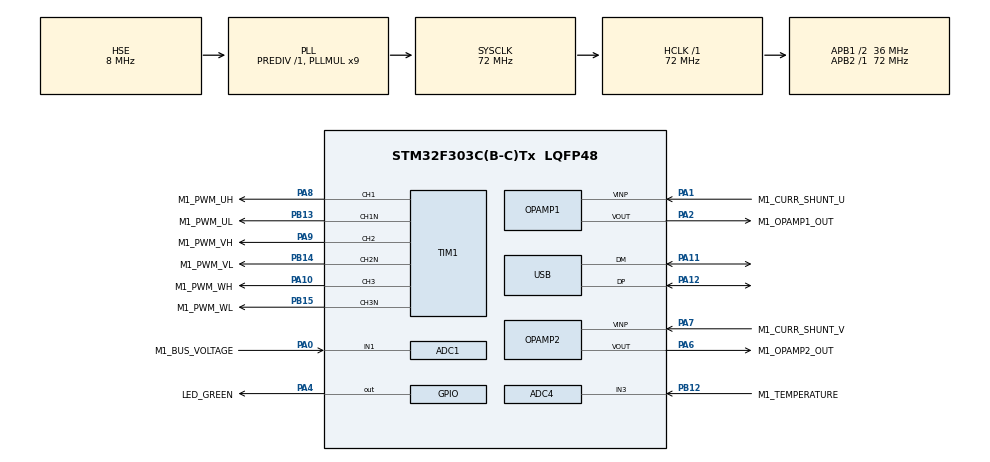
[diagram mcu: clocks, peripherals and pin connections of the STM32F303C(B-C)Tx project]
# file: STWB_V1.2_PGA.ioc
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ADC1.Channel-1\#ChannelRegularConversion=ADC_CHANNEL_1
ADC1.ClockPrescaler=ADC_CLOCK_SYNC_PCLK_DIV4
ADC1.ContinuousConvMode=DISABLE
ADC1.DMAContinuousRequests=DISABLE
ADC1.DataAlign=ADC_DATAALIGN_LEFT
ADC1.DiscontinuousConvMode=DISABLE
ADC1.EOCSelection=ADC_EOC_SINGLE_CONV
ADC1.EnableAnalogWatchDog1=false
ADC1.EnableAnalogWatchDog2=false
ADC1.EnableAnalogWatchDog3=false
ADC1.EnableInjectedConversion=ENABLE
ADC1.EnableRegularConversion=ENABLE
ADC1.ExternalTrigConv=ADC_SOFTWARE_START
ADC1.ExternalTrigConvEdge=ADC_EXTERNALTRIGCONVEDGE_NONE
ADC1.ExternalTrigInjecConv=ADC_EXTERNALTRIGINJECCONV_T1_TRGO
ADC1.ExternalTrigInjecConvEdge=ADC_EXTERNALTRIGINJECCONV_EDGE_RISING
ADC1.InjNumberOfConversion=1
ADC1.InjectedChannel-1\#ChannelInjectedConversion=ADC_CHANNEL_3
ADC1.InjectedConvMode=None
ADC1.InjectedOffset-1\#ChannelInjectedConversion=0
ADC1.InjectedOffsetNumber-1\#ChannelInjectedConversion=ADC_OFFSET_NONE
ADC1.InjectedRank-1\#ChannelInjectedConversion=1
ADC1.InjectedSamplingTime-1\#ChannelInjectedConversion=ADC_SAMPLETIME_7CYCLES_5
ADC1.LowPowerAutoWait=DISABLE
ADC1.NbrOfConversion=1
ADC1.NbrOfConversionFlag=1
ADC1.Offset-1\#ChannelRegularConversion=0
ADC1.OffsetNumber-1\#ChannelRegularConversion=ADC_OFFSET_NONE
ADC1.Overrun=ADC_OVR_DATA_PRESERVED
ADC1.QueueInjectedContext=ENABLE
ADC1.Rank-1\#ChannelRegularConversion=1
ADC1.Resolution=ADC_RESOLUTION_12B
ADC1.SamplingTime-1\#ChannelRegularConversion=ADC_SAMPLETIME_61CYCLES_5
ADC1.ScanConvMode=ADC_SCAN_DISABLE
ADC1.master=1
ADC2.ClockPrescaler=ADC_CLOCK_SYNC_PCLK_DIV4
ADC2.ContinuousConvMode=DISABLE
ADC2.DMAContinuousRequests=DISABLE
ADC2.DataAlign=ADC_DATAALIGN_LEFT
ADC2.DiscontinuousConvMode=DISABLE
ADC2.EOCSelection=ADC_EOC_SINGLE_CONV
ADC2.EnableAnalogWatchDog1=false
ADC2.EnableAnalogWatchDog2=false
ADC2.EnableAnalogWatchDog3=false
ADC2.EnableInjectedConversion=ENABLE
ADC2.EnableRegularConversion=DISABLE
ADC2.ExternalTrigInjecConv=ADC_EXTERNALTRIGINJECCONV_T1_TRGO
ADC2.ExternalTrigInjecConvEdge=ADC_EXTERNALTRIGINJECCONV_EDGE_RISING
ADC2.InjNumberOfConversion=1
ADC2.InjectedChannel-1\#ChannelInjectedConversion=ADC_CHANNEL_3
ADC2.InjectedConvMode=None
ADC2.InjectedOffset-1\#ChannelInjectedConversion=0
ADC2.InjectedOffsetNumber-1\#ChannelInjectedConversion=ADC_OFFSET_NONE
ADC2.InjectedRank-1\#ChannelInjectedConversion=1
ADC2.InjectedSamplingTime-1\#ChannelInjectedConversion=ADC_SAMPLETIME_7CYCLES_5
ADC2.LowPowerAutoWait=DISABLE
ADC2.Overrun=ADC_OVR_DATA_PRESERVED
ADC2.QueueInjectedContext=ENABLE
ADC2.Resolution=ADC_RESOLUTION_12B
ADC2.ScanConvMode=ADC_SCAN_DISABLE
ADC2.master=1
ADC4.Channel-1\#ChannelRegularConversion=ADC_CHANNEL_3
ADC4.ClockPrescaler=ADC_CLOCK_SYNC_PCLK_DIV4
ADC4.ContinuousConvMode=DISABLE
ADC4.DMAContinuousRequests=DISABLE
ADC4.DataAlign=ADC_DATAALIGN_LEFT
ADC4.DiscontinuousConvMode=DISABLE
ADC4.EOCSelection=ADC_EOC_SINGLE_CONV
ADC4.EnableAnalogWatchDog1=false
ADC4.EnableAnalogWatchDog2=false
ADC4.EnableAnalogWatchDog3=false
ADC4.EnableRegularConversion=ENABLE
ADC4.ExternalTrigConv=ADC_SOFTWARE_START
ADC4.ExternalTrigConvEdge=ADC_EXTERNALTRIGCONVEDGE_NONE
ADC4.LowPowerAutoWait=DISABLE
ADC4.NbrOfConversion=1
ADC4.NbrOfConversionFlag=1
ADC4.Offset-1\#ChannelRegularConversion=0
ADC4.OffsetNumber-1\#ChannelRegularConversion=ADC_OFFSET_NONE
ADC4.Overrun=ADC_OVR_DATA_PRESERVED
ADC4.Rank-1\#ChannelRegularConversion=1
ADC4.Resolution=ADC_RESOLUTION_12B
ADC4.SamplingTime-1\#ChannelRegularConversion=ADC_SAMPLETIME_61CYCLES_5
ADC4.ScanConvMode=ADC_SCAN_DISABLE
ADC4.master=1
ExtraMW=MotorControl
ExtraMW.MotorControl.Config=MotorControl
ExtraMW.MotorControl.Mode=MotorControl
ExtraMW.MotorControl.Root=MCSDK_v5.4.4-Full/MotorControl
ExtraMW.MotorControl.Template=templates
Mcu.Family=STM32F3
Mcu.Name=STM32F303C(B-C)Tx
Mcu.Package=LQFP48
MotorControl.ADC_1_PERIPH=ADC1
MotorControl.ADC_2_PERIPH=ADC2
MotorControl.ADC_AHBPERIPH=RCC_AHBPeriph_ADC12
MotorControl.ADC_CLOCK_WB_DIV=4
MotorControl.ADC_CLOCK_WB_FREQ=18
MotorControl.ADC_PERIPH=ADC1
MotorControl.ADC_REFERENCE_VOLTAGE=3.30
MotorControl.ALIGNMENT_ANGLE_DEG=90
MotorControl.ALIGNMENT_DURATION=700
MotorControl.AMPLIFICATION_GAIN=10.67
MotorControl.ANGC={0,0,0,0,0,0,0,0}
MotorControl.BEMF_CONSISTENCY_GAIN=64
MotorControl.BEMF_CONSISTENCY_TOL=64
MotorControl.BKIN1_FILTER=0
MotorControl.BKIN2_FILTER=0
MotorControl.BKIN2_MODE=NONE
MotorControl.BKIN_MODE=NONE
MotorControl.BOARD=CUSTOM
MotorControl.BRKIN2_GPIO_AF=GPIO_AF_2
MotorControl.BRKIN_GPIO_AF=GPIO_AF_12
MotorControl.BUS_VOLTAGE_READING=true
MotorControl.CCMRAM_ENABLED=false
MotorControl.CLOCK_FREQUENCY=CPU_CLK_72_MHZ
MotorControl.CLOCK_SOURCE=EXTERNAL
MotorControl.CONSTANT1_D=20107
MotorControl.CONSTANT1_Q=20107
MotorControl.CONSTANT2_QD=3298
MotorControl.CORD_BEMF_CONSISTENCY_GAIN=64
MotorControl.CORD_BEMF_CONSISTENCY_TOL=64
MotorControl.CORD_F1=8192
MotorControl.CORD_F2=8192
MotorControl.CORD_FIFO_DEPTH_01HZ=64
MotorControl.CORD_FIFO_DEPTH_DPP=64
MotorControl.CORD_GAIN1=-9216
MotorControl.CORD_GAIN2=25044
MotorControl.CORD_MAX_ACCEL_DPPP=106
MotorControl.CORD_MEAS_ERRORS_BEFORE_FAULTS=3
MotorControl.CORD_VARIANCE_THRESHOLD=4
MotorControl.CPU_CLK_72_MHZ=true
MotorControl.CTRBDID=0
MotorControl.CUBE_MX_VER=6.0.1
MotorControl.CURRENT_READING_TOPOLOGY=THREE_SHUNT_INDEPENDENT_RESOURCES
MotorControl.CURR_SAMPLING_TIME=7
MotorControl.DAC_EMULATED=false
MotorControl.DAC_FUNCTIONALITY=false
MotorControl.DAC_TIMER_CH1_GPIO_PIN=LL_GPIO_PIN_0
MotorControl.DAC_TIMER_CH1_GPIO_PORT=GPIOA
MotorControl.DAC_TIMER_CH2_GPIO_PIN=LL_GPIO_PIN_0
MotorControl.DAC_TIMER_CH2_GPIO_PORT=GPIOA
MotorControl.DAC_TIMER_SELECTION=TIM3
MotorControl.DC_CURRENT_RS_MEAS=1.50
MotorControl.DEBUG_DAC_CH1=false
MotorControl.DEBUG_DAC_CH2=false
MotorControl.DEFAULT_CONTROL_MODE=STC_SPEED_MODE
MotorControl.DEFAULT_DAC_CHANNEL_1=MC_PROTOCOL_REG_I_A
MotorControl.DEFAULT_DAC_CHANNEL_2=MC_PROTOCOL_REG_I_B
MotorControl.DEFAULT_DAC_MOTOR=0
MotorControl.DEFAULT_FLUX_COMPONENT=0
MotorControl.DEFAULT_TARGET_SPEED_RPM=886
MotorControl.DEFAULT_TORQUE_COMPONENT=0
MotorControl.DISSIPATIVE_BRAKE_POLARITY=DOUT_ACTIVE_HIGH
MotorControl.DRIVES_NUMBER_SELECTION=SINGLEDRIVE
MotorControl.EMERGENCY2_STOP_GPIO_PIN=LL_GPIO_PIN_11
MotorControl.EMERGENCY2_STOP_GPIO_PORT=GPIOA
MotorControl.EMERGENCY_STOP_GPIO_PIN=LL_GPIO_PIN_11
MotorControl.EMERGENCY_STOP_GPIO_PORT=GPIOA
MotorControl.ENABLE_SL_ALGO_FROM_PHASE=2
MotorControl.ENCODER_AVAILABLE=true
MotorControl.ENCODER_PPR=5000
MotorControl.ENC_AVERAGING_FIFO_DEPTH=16
MotorControl.ENC_A_GPIO_PIN=LL_GPIO_PIN_6
MotorControl.ENC_A_GPIO_PORT=GPIOB
MotorControl.ENC_B_GPIO_PIN=LL_GPIO_PIN_7
MotorControl.ENC_B_GPIO_PORT=GPIOB
MotorControl.ENC_ICx_FILTER=48
MotorControl.ENC_INVERT_SPEED=false
MotorControl.ENC_MEAS_ERRORS_BEFORE_FAULTS=3
MotorControl.ENC_TIMER_REMAPPING=NO_REMAP_TIM4
MotorControl.ENC_TIMER_SELECTION=ENC_TIM4
MotorControl.ENC_USE_CH3=false
MotorControl.EXT_CLK_8_MHZ=true
MotorControl.EXT_CLOCK_FREQUENCY=EXT_CLK_8_MHZ
MotorControl.F1=8192
MotorControl.F2=8192
MotorControl.FEEDBACK_NET_FILTERING=false
MotorControl.FEED_FORWARD_CURRENT_REG_ENABLING=false
MotorControl.FINAL_I_ALIGNMENT=3178
MotorControl.FLUX_WEAKENING_ENABLING=false
MotorControl.FW_KIDIV=32768
MotorControl.FW_KI_GAIN=5000
MotorControl.FW_KPDIV=32768
MotorControl.FW_KP_GAIN=3000
MotorControl.FW_VOLTAGE_REF=985
MotorControl.GAIN1=-9216
MotorControl.GAIN2=25044
MotorControl.H1_GPIO_PIN=LL_GPIO_PIN_0
MotorControl.H1_GPIO_PORT=GPIOA
MotorControl.H2_GPIO_PIN=LL_GPIO_PIN_3
MotorControl.H2_GPIO_PORT=GPIOB
MotorControl.H3_GPIO_PIN=LL_GPIO_PIN_10
MotorControl.H3_GPIO_PORT=GPIOB
MotorControl.HALL_AVERAGING_FIFO_DEPTH=6
MotorControl.HALL_ICx_FILTER=94
MotorControl.HALL_MEAS_ERRORS_BEFORE_FAULTS=3
MotorControl.HALL_MTPA=false
MotorControl.HALL_PHASE_SHIFT=300
MotorControl.HALL_SENSORS_AVAILABLE=false
MotorControl.HALL_SENSORS_PLACEMENT=DEGREES_120
MotorControl.HALL_TIMER_REMAPPING=NO_REMAP_TIM2
MotorControl.HALL_TIMER_SELECTION=HALL_TIM2
MotorControl.HFI_AMPLITUDE=25
MotorControl.HFI_DC_0_COEFF=0.00146
MotorControl.HFI_DC_1_COEFF=0.002921
MotorControl.HFI_DC_2_COEFF=0.00146
MotorControl.HFI_DC_3_COEFF=1.889033
MotorControl.HFI_DC_4_COEFF=-0.894874
MotorControl.HFI_DEBUG_MODE=false
MotorControl.HFI_FREQUENCY=400
MotorControl.HFI_HIFRAMPLSCAN=25
MotorControl.HFI_HP_ID_0_COEFF=0.939693
MotorControl.HFI_HP_ID_1_COEFF=-1.879386
MotorControl.HFI_HP_ID_2_COEFF=0.939693
MotorControl.HFI_HP_ID_3_COEFF=1.875746
MotorControl.HFI_HP_ID_4_COEFF=-0.883026
MotorControl.HFI_IDH_DELAY=32400
MotorControl.HFI_LOCKFREQ=33
MotorControl.HFI_LP_ID_0_COEFF=0.00597
MotorControl.HFI_LP_ID_1_COEFF=0.011941
MotorControl.HFI_LP_ID_2_COEFF=0.00597
MotorControl.HFI_LP_ID_3_COEFF=1.769837
MotorControl.HFI_LP_ID_4_COEFF=-0.793719
MotorControl.HFI_MAXANGLEDIFF=3640
MotorControl.HFI_MINIMUM_SPEED_RPM=402
MotorControl.HFI_NOTCH_IQD_0_COEFF=0.969619
MotorControl.HFI_NOTCH_IQD_1_COEFF=-1.923946
MotorControl.HFI_NOTCH_IQD_2_COEFF=0.969619
MotorControl.HFI_NOTCH_IQD_3_COEFF=1.923946
MotorControl.HFI_NOTCH_IQD_4_COEFF=-0.939237
MotorControl.HFI_NSDETPOINTSSKIP=10
MotorControl.HFI_NSMAXDETPOINTS=20
MotorControl.HFI_NS_MIN_SAT_DIFF=0
MotorControl.HFI_PID_KIDIV=32768
MotorControl.HFI_PID_KI_DEFAULT=400
MotorControl.HFI_PID_KPDIV=16384
MotorControl.HFI_PID_KP_DEFAULT=800
MotorControl.HFI_PLL_KI_DEFAULT=0.00400
MotorControl.HFI_PLL_KP_DEFAULT=0.00060
MotorControl.HFI_RESTARTTIMESEC=0.1
MotorControl.HFI_RESTART_RPM_TH=(((HFI_STO_RPM_TH)+(STO_HFI_RPM_TH))/2)
MotorControl.HFI_REVERT_DIRECTION=true
MotorControl.HFI_SCANROTATIONSNO=3
MotorControl.HFI_SPD_BUFFER_DEPTH_01HZ=64
MotorControl.HFI_STEPANGLE=3640
MotorControl.HFI_STO_RPM_TH=OBS_MINIMUM_SPEED_RPM
MotorControl.HFI_WAITAFTERNS2=4
MotorControl.HFI_WAITBEFORESN=6
MotorControl.HFI_WAITSYNCH=20
MotorControl.HFI_WAITTRACK=20
MotorControl.HIGH_SIDE_BRAKE_STATE=false
MotorControl.HIGH_SIDE_IDLE_STATE=false
MotorControl.HW_COMPLEMENTED_LOW_SIDE=false
MotorControl.HW_DEAD_TIME_NS=100
MotorControl.HW_OV_CURRENT_PROT_BYPASS=false
MotorControl.ID_DEMAG=-3178
MotorControl.INRUSH_CURRLIMIT_AT_POWER_ON=true
MotorControl.INRUSH_CURRLIMIT_CHANGE_AFTER_MS=1000
MotorControl.INRUSH_CURRLIMIT_ENABLING=false
MotorControl.INRUSH_CURRLIMIT_GPIO_PIN=LL_GPIO_PIN_4
MotorControl.INRUSH_CURRLIMIT_GPIO_PORT=GPIOE
MotorControl.INRUSH_CURR_LIMITER_POLARITY=DOUT_ACTIVE_HIGH
MotorControl.INTERNAL_OVERCURRENTPROTECTION=false
MotorControl.INTERNAL_OVERVOLTAGEPROTECTION=false
MotorControl.IPs=NVIC,RCC,SYS,MotorControl,TIM1,OPAMP1,OPAMP2,ADC1,ADC2,TIM4,ADC4,USART3
MotorControl.IQMAX=3178
MotorControl.LCD_JOYSTICK_FUNCTIONALITY=false
MotorControl.LCD_MODE=LCD_FULL
MotorControl.LDLQ_RATIO=1.000
MotorControl.LOW_SIDE_BRAKE_STATE=false
MotorControl.LOW_SIDE_IDLE_STATE=false
MotorControl.LOW_SIDE_SIGNALS_ENABLING=LS_PWM_TIMER
MotorControl.LS=0.000241
MotorControl.MAX_APPLICATION_SPEED=2388
MotorControl.MAX_MODULATION_93_PER_CENT=true
MotorControl.MAX_MODULATION_INDEX=MAX_MODULATION_93_PER_CENT
MotorControl.MCU=STM32F303CB
MotorControl.MCU_TYPE=STM32F303xB
MotorControl.MC_WORKBENCH_VERSION=5.4.4.20160
MotorControl.MEAS_ERRORS_BEFORE_FAULTS=3
MotorControl.MIN_APPLICATION_SPEED=0
MotorControl.MOTOR_MAX_SPEED_RPM=2388
MotorControl.MOTOR_TYPE=PMSM
MotorControl.MOTOR_VOLTAGE_CONSTANT=6.9
MotorControl.MTPA_ENABLING=false
MotorControl.NB_CONSECUTIVE_TESTS=2
MotorControl.NOMINAL_BUS_VOLTAGE_V=24
MotorControl.NOMINAL_CURRENT=3178
MotorControl.OBS_MEAS_ERRORS_BEFORE_FAULTS=3
MotorControl.OBS_MINIMUM_SPEED_RPM=886
MotorControl.OCPA_INVERTINGINPUT=COMPX_InvertingInput_VREF
MotorControl.OCPA_INVERTINGINPUT_GPIO_PIN=LL_GPIO_PIN_4
MotorControl.OCPA_INVERTINGINPUT_GPIO_PORT=GPIOA
MotorControl.OCPA_INVERTINGINPUT_MODE=INT_MODE
MotorControl.OCPA_NONINVERTINGINPUT=COMP1_NonInvertingInput_PA1
MotorControl.OCPA_NONINVERTINGINPUT_GPIO_PIN=LL_GPIO_PIN_1
MotorControl.OCPA_NONINVERTINGINPUT_GPIO_PORT=GPIOA
MotorControl.OCPA_OUTPUT=COMP_Output_TIM1BKIN2
MotorControl.OCPA_OUTPUTPOL=COMP_OutputPol_NonInverted
MotorControl.OCPA_OUTPUT_GPIO_AF=GPIO_AF_8
MotorControl.OCPA_OUTPUT_GPIO_PIN=LL_GPIO_PIN_0
MotorControl.OCPA_OUTPUT_GPIO_PORT=GPIOA
MotorControl.OCPA_OUTPUT_MODE=INT_MODE
MotorControl.OCPA_SELECTION=COMP1
MotorControl.OCPB_INVERTINGINPUT=COMPX_InvertingInput_VREF
MotorControl.OCPB_INVERTINGINPUT_GPIO_PIN=LL_GPIO_PIN_4
MotorControl.OCPB_INVERTINGINPUT_GPIO_PORT=GPIOA
MotorControl.OCPB_INVERTINGINPUT_MODE=INT_MODE
MotorControl.OCPB_NONINVERTINGINPUT=COMP2_NonInvertingInput_PA7
MotorControl.OCPB_NONINVERTINGINPUT_GPIO_PIN=LL_GPIO_PIN_7
MotorControl.OCPB_NONINVERTINGINPUT_GPIO_PORT=GPIOA
MotorControl.OCPB_OUTPUT=COMP_Output_TIM1BKIN2
MotorControl.OCPB_OUTPUTPOL=COMP_OutputPol_NonInverted
MotorControl.OCPB_OUTPUT_GPIO_AF=GPIO_AF_8
MotorControl.OCPB_OUTPUT_GPIO_PIN=LL_GPIO_PIN_2
MotorControl.OCPB_OUTPUT_GPIO_PORT=GPIOA
MotorControl.OCPB_OUTPUT_MODE=INT_MODE
MotorControl.OCPB_SELECTION=COMP2
MotorControl.OCPC_INVERTINGINPUT=COMPX_InvertingInput_VREF
MotorControl.OCPC_INVERTINGINPUT_GPIO_PIN=LL_GPIO_PIN_4
MotorControl.OCPC_INVERTINGINPUT_GPIO_PORT=GPIOA
MotorControl.OCPC_INVERTINGINPUT_MODE=INT_MODE
MotorControl.OCPC_NONINVERTINGINPUT=COMP4_NonInvertingInput_PB0
MotorControl.OCPC_NONINVERTINGINPUT_GPIO_PIN=LL_GPIO_PIN_0
MotorControl.OCPC_NONINVERTINGINPUT_GPIO_PORT=GPIOB
MotorControl.OCPC_OUTPUT=COMP_Output_TIM1BKIN2
MotorControl.OCPC_OUTPUTPOL=COMP_OutputPol_NonInverted
MotorControl.OCPC_OUTPUT_GPIO_AF=GPIO_AF_8
MotorControl.OCPC_OUTPUT_GPIO_PIN=LL_GPIO_PIN_1
MotorControl.OCPC_OUTPUT_GPIO_PORT=GPIOB
MotorControl.OCPC_OUTPUT_MODE=INT_MODE
MotorControl.OCPC_SELECTION=COMP4
MotorControl.OCPREF=23830
MotorControl.OCP_COMP_THRESHOLD=0.50
MotorControl.OCP_FILTER=COMP_Mode_HighSpeed
MotorControl.OCP_INVERTINGINPUT=COMPX_InvertingInput_VREF
MotorControl.OCP_INVERTINGINPUT_GPIO_PIN=LL_GPIO_PIN_4
MotorControl.OCP_INVERTINGINPUT_GPIO_PORT=GPIOA
MotorControl.OCP_INVERTINGINPUT_MODE=INT_MODE
MotorControl.OCP_NONINVERTINGINPUT=COMP2_NonInvertingInput_PA7
MotorControl.OCP_NONINVERTINGINPUT_GPIO_PIN=LL_GPIO_PIN_7
MotorControl.OCP_NONINVERTINGINPUT_GPIO_PORT=GPIOA
MotorControl.OCP_OUTPUT=COMP_Output_TIM1BKIN2
MotorControl.OCP_OUTPUTPOL=COMP_OutputPol_NonInverted
MotorControl.OCP_OUTPUT_GPIO_AF=GPIO_AF_8
MotorControl.OCP_OUTPUT_GPIO_PIN=LL_GPIO_PIN_2
MotorControl.OCP_OUTPUT_GPIO_PORT=GPIOA
MotorControl.OCP_OUTPUT_MODE=INT_MODE
MotorControl.OCP_SELECTION=COMP2
MotorControl.OFST={0,0,0,0,0,0,0,0}
MotorControl.ON_OVER_VOLTAGE=TURN_OFF_PWM
MotorControl.OPAMP1_INVERTINGINPUT=OPAMP1_InvertingInput_PGA
MotorControl.OPAMP1_INVERTINGINPUT_GPIO_PIN=LL_GPIO_PIN_3
MotorControl.OPAMP1_INVERTINGINPUT_GPIO_PORT=GPIOA
MotorControl.OPAMP1_INVERTINGINPUT_MODE=INT_MODE
MotorControl.OPAMP1_NONINVERTINGINPUT_PHA=OPAMP1_NonInvertingInput_PA1
MotorControl.OPAMP1_NONINVERTINGINPUT_PHA_GPIO_PIN=LL_GPIO_PIN_1
MotorControl.OPAMP1_NONINVERTINGINPUT_PHA_GPIO_PORT=GPIOA
MotorControl.OPAMP1_NONINVERTINGINPUT_PHB=OPAMP1_NonInvertingInput_PA7
MotorControl.OPAMP1_NONINVERTINGINPUT_PHB_GPIO_PIN=LL_GPIO_PIN_7
MotorControl.OPAMP1_NONINVERTINGINPUT_PHB_GPIO_PORT=GPIOA
MotorControl.OPAMP1_OUT_GPIO_PIN=LL_GPIO_PIN_2
MotorControl.OPAMP1_OUT_GPIO_PORT=GPIOA
MotorControl.OPAMP1_SELECTION=OPAMP1
MotorControl.OPAMP2_INVERTINGINPUT=OPAMP2_InvertingInput_PGA
MotorControl.OPAMP2_INVERTINGINPUT_GPIO_PIN=LL_GPIO_PIN_5
MotorControl.OPAMP2_INVERTINGINPUT_GPIO_PORT=GPIOA
MotorControl.OPAMP2_INVERTINGINPUT_MODE=INT_MODE
MotorControl.OPAMP2_NONINVERTINGINPUT_PHA=OPAMP2_NonInvertingInput_PB0
MotorControl.OPAMP2_NONINVERTINGINPUT_PHA_GPIO_PIN=LL_GPIO_PIN_0
MotorControl.OPAMP2_NONINVERTINGINPUT_PHA_GPIO_PORT=GPIOB
MotorControl.OPAMP2_NONINVERTINGINPUT_PHB=OPAMP2_NonInvertingInput_PA7
MotorControl.OPAMP2_NONINVERTINGINPUT_PHB_GPIO_PIN=LL_GPIO_PIN_7
MotorControl.OPAMP2_NONINVERTINGINPUT_PHB_GPIO_PORT=GPIOA
MotorControl.OPAMP2_NONINVERTINGINPUT_PHC=OPAMP2_NonInvertingInput_PB0
MotorControl.OPAMP2_NONINVERTINGINPUT_PHC_GPIO_PIN=LL_GPIO_PIN_0
MotorControl.OPAMP2_NONINVERTINGINPUT_PHC_GPIO_PORT=GPIOB
MotorControl.OPAMP2_OUT_GPIO_PIN=LL_GPIO_PIN_6
MotorControl.OPAMP2_OUT_GPIO_PORT=GPIOA
MotorControl.OPAMP2_SELECTION=OPAMP2
MotorControl.OPAMP3_INVERTINGINPUT=OPAMP1_InvertingInput_PGA
MotorControl.OPAMP3_INVERTINGINPUT_GPIO_PIN=LL_GPIO_PIN_0
MotorControl.OPAMP3_INVERTINGINPUT_GPIO_PORT=GPIOA
MotorControl.OPAMP3_INVERTINGINPUT_MODE=INT_MODE
MotorControl.OPAMP3_SELECTION=OPAMP1
MotorControl.OPAMP_INVERTINGINPUT=OPAMP1_InvertingInput_PGA
MotorControl.OPAMP_INVERTINGINPUT_GPIO_PIN=LL_GPIO_PIN_3
MotorControl.OPAMP_INVERTINGINPUT_GPIO_PORT=GPIOA
MotorControl.OPAMP_INVERTINGINPUT_MODE=INT_MODE
MotorControl.OPAMP_NONINVERTINGINPUT=OPAMP1_NonInvertingInput_PA7
MotorControl.OPAMP_NONINVERTINGINPUT_GPIO_PIN=LL_GPIO_PIN_7
MotorControl.OPAMP_NONINVERTINGINPUT_GPIO_PORT=GPIOA
MotorControl.OPAMP_OUT_GPIO_PIN=LL_GPIO_PIN_2
MotorControl.OPAMP_OUT_GPIO_PORT=GPIOA
MotorControl.OPAMP_PGACONNECT=OPAMP_PGAConnect_No
MotorControl.OPAMP_PGAGAIN=OPAMP_OPAMP_PGAGain_16
MotorControl.OPAMP_SELECTION=OPAMP1
MotorControl.OPAMP_TYPE_GAIN=INTERNAL
MotorControl.OPEN_LOOP_FOC=false
MotorControl.OPEN_LOOP_K=44
MotorControl.OPEN_LOOP_OFF=4400
MotorControl.OPEN_LOOP_SPEED_RAMP_DURATION_MS=1000
MotorControl.OPEN_LOOP_SPEED_RPM=100
MotorControl.OPEN_LOOP_VF=false
MotorControl.OPEN_LOOP_VOLTAGE_d=6000
MotorControl.OVERCURR_FEEDBACK_POLARITY=EMSTOP2_ACTIVE_LOW
MotorControl.OVERCURR_PROTECTION_HW_DISABLING=DOUT_ACTIVE_HIGH
MotorControl.OVPREF=23830
MotorControl.OVP_FILTER=COMP_Mode_HighSpeed
MotorControl.OVP_INVERTINGINPUT=COMPX_InvertingInput_VREF
MotorControl.OVP_INVERTINGINPUT_GPIO_PIN=LL_GPIO_PIN_4
MotorControl.OVP_INVERTINGINPUT_GPIO_PORT=GPIOA
MotorControl.OVP_INVERTINGINPUT_MODE=INT_MODE
MotorControl.OVP_NONINVERTINGINPUT=COMP7_NonInvertingInput_PA0
MotorControl.OVP_NONINVERTINGINPUT_GPIO_PIN=LL_GPIO_PIN_0
MotorControl.OVP_NONINVERTINGINPUT_GPIO_PORT=GPIOA
MotorControl.OVP_OUTPUT=COMP_Output_TIM1BKIN
MotorControl.OVP_OUTPUTPOL=COMP_OutputPol_NonInverted
MotorControl.OVP_OUTPUT_GPIO_AF=GPIO_AF_3
MotorControl.OVP_OUTPUT_GPIO_PIN=LL_GPIO_PIN_2
MotorControl.OVP_OUTPUT_GPIO_PORT=GPIOC
MotorControl.OVP_OUTPUT_MODE=INT_MODE
MotorControl.OVP_SELECTION=COMP7
MotorControl.OV_CURR_BYPASS_GPIO_PIN=LL_GPIO_PIN_5
MotorControl.OV_CURR_BYPASS_GPIO_PORT=GPIOE
MotorControl.OV_TEMPERATURE_HYSTERESIS_C=10
MotorControl.OV_TEMPERATURE_PROT_ENABLING=true
MotorControl.OV_TEMPERATURE_THRESHOLD_C=70
MotorControl.OV_VOLTAGE_PROT_ENABLING=false
MotorControl.OV_VOLTAGE_THRESHOLD_V=32
MotorControl.PHASE1_DURATION=1000
MotorControl.PHASE1_FINAL_CURRENT=3178
MotorControl.PHASE1_FINAL_SPEED_RPM=0
MotorControl.PHASE2_DURATION=1968
MotorControl.PHASE2_FINAL_CURRENT=3178
MotorControl.PHASE2_FINAL_SPEED_RPM=984
MotorControl.PHASE3_DURATION=0
MotorControl.PHASE3_FINAL_CURRENT=3178
MotorControl.PHASE3_FINAL_SPEED_RPM=984
MotorControl.PHASE4_DURATION=0
MotorControl.PHASE4_FINAL_CURRENT=3178
MotorControl.PHASE4_FINAL_SPEED_RPM=984
MotorControl.PHASE5_DURATION=0
MotorControl.PHASE5_FINAL_CURRENT=3178
MotorControl.PHASE5_FINAL_SPEED_RPM=984
MotorControl.PHASE_CURRENTS_ADC=ADC1_2
MotorControl.PHASE_CURRENTS_CHANNEL=ADC_CHANNEL_9
MotorControl.PHASE_CURRENTS_GPIO_PIN=LL_GPIO_PIN_3
MotorControl.PHASE_CURRENTS_GPIO_PORT=GPIOC
MotorControl.PHASE_UH_GPIO_AF=GPIO_AF_6
MotorControl.PHASE_UH_GPIO_PIN=LL_GPIO_PIN_8
MotorControl.PHASE_UH_GPIO_PORT=GPIOA
MotorControl.PHASE_UH_POLARITY=H_ACTIVE_HIGH
MotorControl.PHASE_UL_GPIO_AF=GPIO_AF_6
MotorControl.PHASE_UL_GPIO_PIN=LL_GPIO_PIN_13
MotorControl.PHASE_UL_GPIO_PORT=GPIOB
MotorControl.PHASE_UL_POLARITY=L_ACTIVE_HIGH
MotorControl.PHASE_U_CURR_ADC=ADC1
MotorControl.PHASE_U_CURR_CHANNEL=ADC_CHANNEL_3
MotorControl.PHASE_U_GPIO_PIN=LL_GPIO_PIN_2
MotorControl.PHASE_U_GPIO_PORT=GPIOA
MotorControl.PHASE_VH_GPIO_AF=GPIO_AF_6
MotorControl.PHASE_VH_GPIO_PIN=LL_GPIO_PIN_9
MotorControl.PHASE_VH_GPIO_PORT=GPIOA
MotorControl.PHASE_VH_POLARITY=H_ACTIVE_HIGH
MotorControl.PHASE_VL_GPIO_AF=GPIO_AF_6
MotorControl.PHASE_VL_GPIO_PIN=LL_GPIO_PIN_14
MotorControl.PHASE_VL_GPIO_PORT=GPIOB
MotorControl.PHASE_VL_POLARITY=L_ACTIVE_HIGH
MotorControl.PHASE_V_CURR_ADC=ADC2
MotorControl.PHASE_V_CURR_CHANNEL=ADC_CHANNEL_3
MotorControl.PHASE_V_GPIO_PIN=LL_GPIO_PIN_6
MotorControl.PHASE_V_GPIO_PORT=GPIOA
MotorControl.PHASE_WH_GPIO_AF=GPIO_AF_6
MotorControl.PHASE_WH_GPIO_PIN=LL_GPIO_PIN_10
MotorControl.PHASE_WH_GPIO_PORT=GPIOA
MotorControl.PHASE_WH_POLARITY=H_ACTIVE_HIGH
MotorControl.PHASE_WL_GPIO_AF=GPIO_AF_4
MotorControl.PHASE_WL_GPIO_PIN=LL_GPIO_PIN_15
MotorControl.PHASE_WL_GPIO_PORT=GPIOB
MotorControl.PHASE_WL_POLARITY=L_ACTIVE_HIGH
MotorControl.PHASE_W_CURR_ADC=ADC1_2
MotorControl.PHASE_W_CURR_CHANNEL=ADC_CHANNEL_6
MotorControl.PHASE_W_GPIO_PIN=LL_GPIO_PIN_0
MotorControl.PHASE_W_GPIO_PORT=GPIOC
MotorControl.PID_FLUX_KD_DEFAULT=100
MotorControl.PID_FLUX_KI_DEFAULT=3816
MotorControl.PID_FLUX_KP_DEFAULT=3816
MotorControl.PID_SPEED_KD_DEFAULT=0
MotorControl.PID_SPEED_KI_DEFAULT=169
MotorControl.PID_SPEED_KP_DEFAULT=2588
MotorControl.PID_TORQUE_KD_DEFAULT=100
MotorControl.PID_TORQUE_KI_DEFAULT=3816
MotorControl.PID_TORQUE_KP_DEFAULT=3816
MotorControl.PLL_KI_GAIN=24
MotorControl.PLL_KP_GAIN=699
MotorControl.POLE_PAIR_NUM=11
MotorControl.POSITION_CTRL_ENABLING=false
MotorControl.PWBDID=0
MotorControl.PWM_FREQUENCY=20000
MotorControl.PWM_TIMER_REMAPPING=PWM_NO_REMAP
MotorControl.PWM_TIMER_SELECTION=PWM_TIM1
MotorControl.REGCONVADC=ADC1
MotorControl.REGULATION_EXECUTION_RATE=1
MotorControl.RS=2.41
MotorControl.RSHUNT=0.01000
MotorControl.RTOS=NONE
MotorControl.R_BRAKE_GPIO_PIN=LL_GPIO_PIN_5
MotorControl.R_BRAKE_GPIO_PORT=GPIOE
MotorControl.R_BRAKE_SWITCH_OFF_THRES_V=26
MotorControl.SEGDIV=0
MotorControl.SERIAL_COMMUNICATION=false
MotorControl.SERIAL_COM_CHANNEL1=MC_PROTOCOL_REG_I_A
MotorControl.SERIAL_COM_CHANNEL2=MC_PROTOCOL_REG_I_A
MotorControl.SERIAL_COM_MODE=COM_BIDIRECTIONAL
MotorControl.SERIAL_COM_MOTOR=0
MotorControl.SHARED_SIGNAL_ENABLE=false
MotorControl.SINGLEDRIVE=true
MotorControl.SPD_DIFFERENTIAL_TERM_ENABLING=false
MotorControl.SPEED_BAND_LOWER_LIMIT=15
MotorControl.SPEED_BAND_UPPER_LIMIT=17
MotorControl.SPEED_LOOP_FREQUENCY_HZ=1000
MotorControl.SPEED_SENSOR_SELECTION=STATE_OBSERVER_PLL
MotorControl.SP_KDDIV=16
MotorControl.SP_KIDIV=16384
MotorControl.SP_KPDIV=512
MotorControl.STARTING_ANGLE_DEG=0
MotorControl.START_STOP_BTN=false
MotorControl.START_STOP_GPIO_PIN=LL_GPIO_PIN_6
MotorControl.START_STOP_GPIO_PORT=GPIOE
MotorControl.START_STOP_POLARITY=DIN_ACTIVE_LOW
MotorControl.START_STOP_POLARITY_EDGE=GPIO_NOPULL
MotorControl.STATE_OBSERVER_PLL=true
MotorControl.STM32F303xB=true
MotorControl.STO_FIFO_DEPTH_01HZ=64
MotorControl.STO_FIFO_DEPTH_DPP=64
MotorControl.STO_HFI_RPM_TH=460
MotorControl.SW_DEADTIME_NS=135
MotorControl.SW_OV_CURRENT_PROT_ENABLING=false
MotorControl.T0_C=25
MotorControl.TEMPERATURE_READING=true
MotorControl.TEMP_ADC_SAMPLING_TIME=61
MotorControl.TEMP_FDBK_ADC=ADC4
MotorControl.TEMP_FDBK_CHANNEL=ADC_CHANNEL_3
MotorControl.TEMP_FDBK_GPIO_PIN=LL_GPIO_PIN_12
MotorControl.TEMP_FDBK_GPIO_PORT=GPIOB
MotorControl.TFDIFFERENTIAL_TERM_ENABLING=false
MotorControl.TF_KDDIV=8192
MotorControl.TF_KIDIV=4096
MotorControl.TF_KPDIV=2048
MotorControl.THREE_SHUNT_INDEPENDENT_RESOURCES=true
MotorControl.TNOISE_NS=2550
MotorControl.TRANSITION_DURATION=25
MotorControl.TRISE_NS=2555
MotorControl.T_MAX=70
MotorControl.UD_VOLTAGE_THRESHOLD_V=18
MotorControl.USART_REMAPPING=NO_REMAP_USART3
MotorControl.USART_RX_GPIO_PIN=LL_GPIO_PIN_11
MotorControl.USART_RX_GPIO_PORT=GPIOB
MotorControl.USART_SELECTION=USE_USART3
MotorControl.USART_SPEED=115200
MotorControl.USART_TX_GPIO_PIN=LL_GPIO_PIN_10
MotorControl.USART_TX_GPIO_PORT=GPIOB
MotorControl.USE_3OPAMPS=false
MotorControl.USE_INTERNAL_OPAMP=true
MotorControl.UV_VOLTAGE_PROT_ENABLING=false
MotorControl.V0_V=0.290
MotorControl.VARIANCE_THRESHOLD=0.1
MotorControl.VBUS_ADC=ADC1
MotorControl.VBUS_ADC_SAMPLING_TIME=61
MotorControl.VBUS_CHANNEL=ADC_CHANNEL_1
MotorControl.VBUS_GPIO_PIN=LL_GPIO_PIN_0
MotorControl.VBUS_GPIO_PORT=GPIOA
MotorControl.VBUS_PARTITIONING_FACTOR=0.0086
MotorControl.WB_to_Mx_template_version=20-04-17
MotorControl.WB_to_Mx_version=1.1.0
MotorControl.dV_dT=0.025
NVIC.ADC1_2_IRQn=true\:2\:0\:true\:true\:false\:3\:true\:true
NVIC.PriorityGroup=NVIC_PRIORITYGROUP_3
NVIC.TIM1_BRK_TIM15_IRQn=true\:4\:1\:true\:true\:false\:1\:true\:true
NVIC.TIM1_UP_TIM16_IRQn=true\:0\:0\:false\:true\:false\:2\:true\:true
NVIC.USB_LP_IRQn=true\:0\:0\:false\:false\:true\:false\:true
OPAMP1.PgaGain=OPAMP_PGA_GAIN_16
OPAMP1.SelfCalibration=Disable
OPAMP2.PgaGain=OPAMP_PGA_GAIN_16
OPAMP2.SelfCalibration=Disable
PA0.GPIO_Label=M1_BUS_VOLTAGE
PA0.Mode=IN1-Single-Ended
PA0.Signal=ADC1_IN1
PA1.GPIO_Label=M1_CURR_SHUNT_U
PA1.Mode=PGA Not Connected
PA1.Signal=OPAMP1_VINP
PA10.GPIO_Label=M1_PWM_WH
PA10.GPIO_PuPd=GPIO_PULLDOWN
PA10.GPIO_Speed=GPIO_SPEED_FREQ_HIGH
PA10.Signal=S_TIM1_CH3
PA11.Mode=Device
PA11.Signal=USB_DM
PA12.GPIO_PuPd=GPIO_PULLUP
PA12.Mode=Device
PA12.Signal=USB_DP
PA2.GPIO_Label=M1_OPAMP1_OUT
PA2.Signal=SharedAnalog_PA2
PA4.GPIO_Label=LED_GREEN
PA4.GPIO_Speed=GPIO_SPEED_FREQ_HIGH
PA4.Signal=GPIO_Output
PA6.GPIO_Label=M1_OPAMP2_OUT
PA6.Signal=SharedAnalog_PA6
PA7.GPIO_Label=M1_CURR_SHUNT_V
PA7.Mode=PGA Not Connected
PA7.Signal=OPAMP2_VINP
PA8.GPIO_Label=M1_PWM_UH
PA8.GPIO_PuPd=GPIO_PULLDOWN
PA8.GPIO_Speed=GPIO_SPEED_FREQ_HIGH
PA8.Signal=S_TIM1_CH1
PA9.GPIO_Label=M1_PWM_VH
PA9.GPIO_PuPd=GPIO_PULLDOWN
PA9.GPIO_Speed=GPIO_SPEED_FREQ_HIGH
PA9.Signal=S_TIM1_CH2
PB0.GPIO_Label=M1_CURR_SHUNT_W
PB0.Signal=OPAMP2_VINP_SEC
PB12.GPIO_Label=M1_TEMPERATURE
PB12.Mode=IN3-Single-Ended
PB12.Signal=ADC4_IN3
PB13.GPIO_Label=M1_PWM_UL
PB13.GPIO_PuPd=GPIO_PULLDOWN
PB13.GPIO_Speed=GPIO_SPEED_FREQ_HIGH
PB13.Mode=PWM Generation1 CH1 CH1N
PB13.Signal=TIM1_CH1N
PB14.GPIO_Label=M1_PWM_VL
PB14.GPIO_PuPd=GPIO_PULLDOWN
PB14.GPIO_Speed=GPIO_SPEED_FREQ_HIGH
PB14.Mode=PWM Generation2 CH2 CH2N
PB14.Signal=TIM1_CH2N
PB15.GPIO_Label=M1_PWM_WL
PB15.GPIO_PuPd=GPIO_PULLDOWN
PB15.GPIO_Speed=GPIO_SPEED_FREQ_HIGH
PB15.Mode=PWM Generation3 CH3 CH3N
PB15.Signal=TIM1_CH3N
PB6.GPIO_Label=M1_ENCODER_A
PB6.Signal=S_TIM4_CH1
PB7.GPIO_Label=M1_ENCODER_B
PB7.Signal=S_TIM4_CH2
PF0-OSC_IN.Mode=HSE-External-Oscillator
PF0-OSC_IN.Signal=RCC_OSC_IN
PF1-OSC_OUT.Mode=HSE-External-Oscillator
PF1-OSC_OUT.Signal=RCC_OSC_OUT
ProjectManager.HeapSize=0x200
ProjectManager.StackSize=0x400
ProjectManager.TargetToolchain=MDK-ARM V5
RCC.AHBFreq_Value=72000000
RCC.APB1CLKDivider=RCC_HCLK_DIV2
RCC.APB1Freq_Value=36000000
RCC.APB1TimFreq_Value=72000000
RCC.APB2Freq_Value=72000000
RCC.APB2TimFreq_Value=72000000
RCC.CortexFreq_Value=72000000
RCC.HCLKFreq_Value=72000000
RCC.HSE_VALUE=8000000
RCC.HSI_VALUE=8000000
RCC.LSE_VALUE=32768
RCC.PLLMUL=RCC_PLL_MUL9
RCC.PRESCALERUSB=RCC_USBCLKSOURCE_PLL_DIV1_5
RCC.SYSCLKFreq_VALUE=72000000
RCC.SYSCLKSourceVirtual=RCC_SYSCLKSOURCE_PLLCLK
RCC.TIM1Selection=RCC_TIM1CLK_PLLCLK
RCC.TIM8Selection=RCC_TIM8CLK_PLLCLK
RCC.USBFreq_Value=48000000
SH.S_TIM1_CH1.0=TIM1_CH1,PWM Generation1 CH1 CH1N
SH.S_TIM1_CH2.0=TIM1_CH2,PWM Generation2 CH2 CH2N
SH.S_TIM1_CH3.0=TIM1_CH3,PWM Generation3 CH3 CH3N
SH.S_TIM4_CH1.0=TIM4_CH1
SH.S_TIM4_CH2.0=TIM4_CH2
SH.SharedAnalog_PA2.0=OPAMP1_VOUT,PGA Not Connected
SH.SharedAnalog_PA2.1=ADC1_IN3,IN3-Single-Ended
SH.SharedAnalog_PA6.0=OPAMP2_VOUT,PGA Not Connected
SH.SharedAnalog_PA6.1=ADC2_IN3,IN3-Single-Ended
TIM1.AutoReloadPreload=TIM_AUTORELOAD_PRELOAD_DISABLE
TIM1.AutomaticOutput=TIM_AUTOMATICOUTPUT_DISABLE
TIM1.Break2Filter=0
TIM1.Break2Polarity=TIM_BREAK2POLARITY_LOW
TIM1.Break2State=TIM_BREAK2_DISABLE
TIM1.BreakFilter=0
TIM1.BreakPolarity=TIM_BREAKPOLARITY_HIGH
TIM1.BreakState=TIM_BREAK_DISABLE
TIM1.Channel=TIM_CHANNEL_4
TIM1.Channel-PWM\ Generation1\ CH1\ CH1N=TIM_CHANNEL_1
TIM1.Channel-PWM\ Generation2\ CH2\ CH2N=TIM_CHANNEL_2
TIM1.Channel-PWM\ Generation3\ CH3\ CH3N=TIM_CHANNEL_3
TIM1.Channel-PWM\ Generation4\ No\ Output=TIM_CHANNEL_4
TIM1.ClearInputSource=TIM_CLEARINPUTSOURCE_NONE
TIM1.ClockDivision=TIM_CLOCKDIVISION_DIV2
TIM1.CounterMode=TIM_COUNTERMODE_CENTERALIGNED1
TIM1.DeadTime=((DEAD_TIME_COUNTS) / 2)
TIM1.LockLevel=TIM_LOCKLEVEL_1
TIM1.OCFastMode_PWM=TIM_OCFAST_DISABLE
TIM1.OCIdleState_1=TIM_OCIDLESTATE_RESET
TIM1.OCIdleState_2=TIM_OCIDLESTATE_RESET
TIM1.OCIdleState_3=TIM_OCIDLESTATE_RESET
TIM1.OCIdleState_4=TIM_OCIDLESTATE_RESET
TIM1.OCIdleState_5=TIM_OCIDLESTATE_RESET
TIM1.OCIdleState_6=TIM_OCIDLESTATE_RESET
TIM1.OCMode_PWM-PWM\ Generation1\ CH1\ CH1N=TIM_OCMODE_PWM1
TIM1.OCMode_PWM-PWM\ Generation2\ CH2\ CH2N=TIM_OCMODE_PWM1
TIM1.OCMode_PWM-PWM\ Generation3\ CH3\ CH3N=TIM_OCMODE_PWM1
TIM1.OCMode_PWM-PWM\ Generation4\ No\ Output=TIM_OCMODE_PWM2
TIM1.OCNIdleState_1=TIM_OCNIDLESTATE_RESET
TIM1.OCNIdleState_2=TIM_OCNIDLESTATE_RESET
TIM1.OCNIdleState_3=TIM_OCNIDLESTATE_RESET
TIM1.OCNPolarity_1=TIM_OCNPOLARITY_HIGH
TIM1.OCNPolarity_2=TIM_OCNPOLARITY_HIGH
TIM1.OCNPolarity_3=TIM_OCNPOLARITY_HIGH
TIM1.OCPolarity_1=TIM_OCPOLARITY_HIGH
TIM1.OCPolarity_2=TIM_OCPOLARITY_HIGH
TIM1.OCPolarity_3=TIM_OCPOLARITY_HIGH
TIM1.OCPolarity_4=TIM_OCPOLARITY_HIGH
TIM1.OCPolarity_5=TIM_OCPOLARITY_HIGH
TIM1.OCPolarity_6=TIM_OCPOLARITY_HIGH
TIM1.OffStateIDLEMode=TIM_OSSI_ENABLE
TIM1.OffStateRunMode=TIM_OSSR_ENABLE
TIM1.Period=((PWM_PERIOD_CYCLES) / 2)
TIM1.Prescaler=((TIM_CLOCK_DIVIDER) - 1)
TIM1.Pulse-PWM\ Generation1\ CH1=((PWM_PERIOD_CYCLES) / 4)
TIM1.Pulse-PWM\ Generation2\ CH2=((PWM_PERIOD_CYCLES) / 4)
TIM1.Pulse-PWM\ Generation3\ CH3=((PWM_PERIOD_CYCLES) / 4)
TIM1.Pulse-PWM\ Generation4\ No\ Output=(((PWM_PERIOD_CYCLES) / 2) - (HTMIN))
TIM1.Pulse-PWM\ Generation5\ No\ Output=(((PWM_PERIOD_CYCLES) / 2) + 1)
TIM1.Pulse-PWM\ Generation6\ No\ Output=(((PWM_PERIOD_CYCLES) / 2) + 1)
TIM1.RepetitionCounter=(REP_COUNTER)
TIM1.TIM_MasterOutputTrigger=TIM_TRGO_OC4REF
TIM1.TIM_MasterOutputTrigger2=TIM_TRGO2_RESET
TIM1.TIM_MasterSlaveMode=TIM_MASTERSLAVEMODE_DISABLE
TIM1.TIM_SlaveMode=TIM_SLAVEMODE_TRIGGER
USB_DEVICE.CLASS_NAME_FS=CDC
USB_DEVICE.VirtualMode=Cdc
USB_DEVICE.VirtualModeFS=Cdc_FS
VP_MotorControl_MC_ENABLED.Mode=Enabled
VP_TIM1_VS_ClockSourceITR.Mode=TriggerSource_ITR1
VP_TIM1_VS_ControllerModeTrigger.Mode=Trigger Mode
VP_TIM1_VS_no_output4.Mode=PWM Generation4 No Output
VP_USB_DEVICE_VS_USB_DEVICE_CDC_FS.Mode=CDC_FS
board=custom

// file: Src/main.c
/* USER CODE BEGIN Header */
/**
  ******************************************************************************
  * @file           : main.c
  * @brief          : Main program body
  ******************************************************************************
  * @attention
  *
  * <h2><center>&copy; Copyright (c) 2020 STMicroelectronics.
  * All rights reserved.</center></h2>
  *
  * This software component is licensed by ST under Ultimate Liberty license
  * SLA0044, the "License"; You may not use this file except in compliance with
  * the License. You may obtain a copy of the License at:
  *                             www.st.com/SLA0044
  *
  ******************************************************************************
  */
/* USER CODE END Header */
#include "main.h"
#include "adc.h"
#include "motorcontrol.h"
#include "opamp.h"
#include "tim.h"
#include "usb_device.h"
#include "gpio.h"

/* USER CODE BEGIN Includes */
#include "board.h"
#include "filter.h"
#include "bsp_usart3.h"
#include "control.h"
#include "bsp_at24cxx.h"

/* USER CODE END Includes */

void SystemClock_Config(void);
static void MX_NVIC_Init(void);

int main(void)
{

  /* MCU Configuration--------------------------------------------------------*/

  /* Reset of all peripherals, Initializes the Flash interface and the Systick. */
  HAL_Init();

  /* Configure the system clock */
  SystemClock_Config();

  /* Initialize all configured peripherals */
  MX_GPIO_Init();
  MX_ADC1_Init();
  MX_ADC2_Init();
  MX_ADC4_Init();
  MX_OPAMP1_Init();
  MX_OPAMP2_Init();
  MX_TIM1_Init();
  MX_MotorControl_Init();
  MX_USB_DEVICE_Init();

  /* Initialize interrupts */
  MX_NVIC_Init();
  /* USER CODE BEGIN 2 */
	TDT_Board_ALL_Init();

	MC_StartMotor1();

  /* USER CODE END 2 */

  /* Infinite loop */
  /* USER CODE BEGIN WHILE */
  while (1)
  {
		if(MotorControl.info.eeprom_write == 1)
		{
				MC_StopMotor1();
				HAL_Delay(1000);
				EEPROM_WriteParameter();
				HAL_Delay(1000);
				MC_StartMotor1();
				MotorControl.info.eeprom_write = 0;
		}

    /* USER CODE END WHILE */
  }
}

void SystemClock_Config(void)
{
  RCC_OscInitTypeDef RCC_OscInitStruct = {0};
  RCC_ClkInitTypeDef RCC_ClkInitStruct = {0};
  RCC_PeriphCLKInitTypeDef PeriphClkInit = {0};

  /** Initializes the RCC Oscillators according to the specified parameters
  * in the RCC_OscInitTypeDef structure.
  */
  RCC_OscInitStruct.OscillatorType = RCC_OSCILLATORTYPE_HSE;
  RCC_OscInitStruct.HSEState = RCC_HSE_ON;
  RCC_OscInitStruct.HSEPredivValue = RCC_HSE_PREDIV_DIV1;
  RCC_OscInitStruct.HSIState = RCC_HSI_ON;
  RCC_OscInitStruct.PLL.PLLState = RCC_PLL_ON;
  RCC_OscInitStruct.PLL.PLLSource = RCC_PLLSOURCE_HSE;
  RCC_OscInitStruct.PLL.PLLMUL = RCC_PLL_MUL9;
  if (HAL_RCC_OscConfig(&RCC_OscInitStruct) != HAL_OK)
  {
    Error_Handler();
  }
  /** Initializes the CPU, AHB and APB buses clocks
  */
  RCC_ClkInitStruct.ClockType = RCC_CLOCKTYPE_HCLK|RCC_CLOCKTYPE_SYSCLK
                              |RCC_CLOCKTYPE_PCLK1|RCC_CLOCKTYPE_PCLK2;
  RCC_ClkInitStruct.SYSCLKSource = RCC_SYSCLKSOURCE_PLLCLK;
  RCC_ClkInitStruct.AHBCLKDivider = RCC_SYSCLK_DIV1;
  RCC_ClkInitStruct.APB1CLKDivider = RCC_HCLK_DIV2;
  RCC_ClkInitStruct.APB2CLKDivider = RCC_HCLK_DIV1;

  if (HAL_RCC_ClockConfig(&RCC_ClkInitStruct, FLASH_LATENCY_2) != HAL_OK)
  {
    Error_Handler();
  }
  PeriphClkInit.PeriphClockSelection = RCC_PERIPHCLK_USB|RCC_PERIPHCLK_TIM1;
  PeriphClkInit.USBClockSelection = RCC_USBCLKSOURCE_PLL_DIV1_5;
  PeriphClkInit.Tim1ClockSelection = RCC_TIM1CLK_PLLCLK;
  if (HAL_RCCEx_PeriphCLKConfig(&PeriphClkInit) != HAL_OK)
  {
    Error_Handler();
  }
}

/**
  * @brief NVIC Configuration.
  * @retval None
  */
static void MX_NVIC_Init(void)
{
  /* TIM1_BRK_TIM15_IRQn interrupt configuration */
  HAL_NVIC_SetPriority(TIM1_BRK_TIM15_IRQn, 4, 1);
  HAL_NVIC_EnableIRQ(TIM1_BRK_TIM15_IRQn);
  /* TIM1_UP_TIM16_IRQn interrupt configuration */
  HAL_NVIC_SetPriority(TIM1_UP_TIM16_IRQn, 0, 0);
  HAL_NVIC_EnableIRQ(TIM1_UP_TIM16_IRQn);
  /* ADC1_2_IRQn interrupt configuration */
  HAL_NVIC_SetPriority(ADC1_2_IRQn, 0, 1);
  HAL_NVIC_EnableIRQ(ADC1_2_IRQn);
}

void Error_Handler(void)
{
}

/************************ (C) COPYRIGHT STMicroelectronics *****END OF FILE****/
